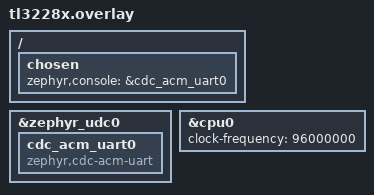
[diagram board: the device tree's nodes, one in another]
/*
 * Copyright (c) 2024 Telink Semiconductor
 *
 * SPDX-License-Identifier: Apache-2.0
 */

/ {
	chosen {
		zephyr,console = &cdc_acm_uart0;
	};
};

&zephyr_udc0 {
	cdc_acm_uart0: cdc_acm_uart0 {
		compatible = "zephyr,cdc-acm-uart";
	};
};

&cpu0 {
	clock-frequency = <96000000>;		/* USB0 digital voltage must be 1.1V and HCLK min's 48M */
};


